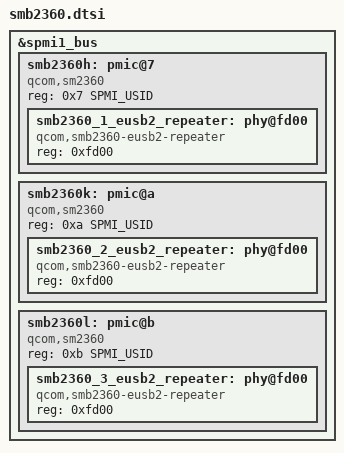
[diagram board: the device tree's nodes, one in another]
// SPDX-License-Identifier: BSD-3-Clause
/*
 * Copyright (c) 2023, Linaro Limited
 */

#include <dt-bindings/interrupt-controller/irq.h>
#include <dt-bindings/spmi/spmi.h>

/ {
};

&spmi1_bus {
	smb2360h: pmic@7 {
		compatible = "qcom,sm2360", "qcom,spmi-pmic";
		reg = <0x7 SPMI_USID>;
		#address-cells = <1>;
		#size-cells = <0>;

		smb2360_1_eusb2_repeater: phy@fd00 {
			compatible = "qcom,smb2360-eusb2-repeater";
			reg = <0xfd00>;
			#phy-cells = <0>;
		};
	};

	smb2360k: pmic@a {
		compatible = "qcom,sm2360", "qcom,spmi-pmic";
		reg = <0xa SPMI_USID>;
		#address-cells = <1>;
		#size-cells = <0>;

		smb2360_2_eusb2_repeater: phy@fd00 {
			compatible = "qcom,smb2360-eusb2-repeater";
			reg = <0xfd00>;
			#phy-cells = <0>;
		};
	};

	smb2360l: pmic@b {
		compatible = "qcom,sm2360", "qcom,spmi-pmic";
		reg = <0xb SPMI_USID>;
		#address-cells = <1>;
		#size-cells = <0>;

		smb2360_3_eusb2_repeater: phy@fd00 {
			compatible = "qcom,smb2360-eusb2-repeater";
			reg = <0xfd00>;
			#phy-cells = <0>;
		};
	};
};
